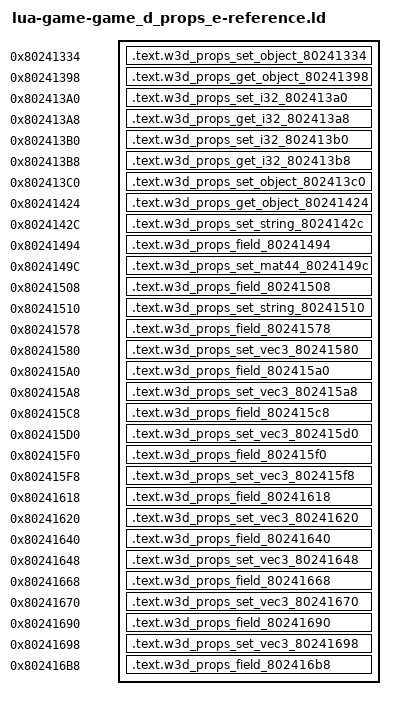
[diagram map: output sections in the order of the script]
/* Generated reference-only placements. All bodies are source-built. */
OUTPUT_FORMAT("elf32-powerpc")
OUTPUT_ARCH(powerpc)
ENTRY(w3d_props_set_object_80241334)
_SDA_BASE_ = 0x804b2540;
_SDA2_BASE_ = 0x804c2540;
w3d_string_release_header = 0x8020bb2c;
SECTIONS {
  .text.w3d_props_set_object_80241334 0x80241334 : { *(.text.w3d_props_set_object_80241334) }
  .text.w3d_props_get_object_80241398 0x80241398 : { *(.text.w3d_props_get_object_80241398) }
  .text.w3d_props_set_i32_802413a0 0x802413a0 : { *(.text.w3d_props_set_i32_802413a0) }
  .text.w3d_props_get_i32_802413a8 0x802413a8 : { *(.text.w3d_props_get_i32_802413a8) }
  .text.w3d_props_set_i32_802413b0 0x802413b0 : { *(.text.w3d_props_set_i32_802413b0) }
  .text.w3d_props_get_i32_802413b8 0x802413b8 : { *(.text.w3d_props_get_i32_802413b8) }
  .text.w3d_props_set_object_802413c0 0x802413c0 : { *(.text.w3d_props_set_object_802413c0) }
  .text.w3d_props_get_object_80241424 0x80241424 : { *(.text.w3d_props_get_object_80241424) }
  .text.w3d_props_set_string_8024142c 0x8024142c : { *(.text.w3d_props_set_string_8024142c) }
  .text.w3d_props_field_80241494 0x80241494 : { *(.text.w3d_props_field_80241494) }
  .text.w3d_props_set_mat44_8024149c 0x8024149c : { *(.text.w3d_props_set_mat44_8024149c) }
  .text.w3d_props_field_80241508 0x80241508 : { *(.text.w3d_props_field_80241508) }
  .text.w3d_props_set_string_80241510 0x80241510 : { *(.text.w3d_props_set_string_80241510) }
  .text.w3d_props_field_80241578 0x80241578 : { *(.text.w3d_props_field_80241578) }
  .text.w3d_props_set_vec3_80241580 0x80241580 : { *(.text.w3d_props_set_vec3_80241580) }
  .text.w3d_props_field_802415a0 0x802415a0 : { *(.text.w3d_props_field_802415a0) }
  .text.w3d_props_set_vec3_802415a8 0x802415a8 : { *(.text.w3d_props_set_vec3_802415a8) }
  .text.w3d_props_field_802415c8 0x802415c8 : { *(.text.w3d_props_field_802415c8) }
  .text.w3d_props_set_vec3_802415d0 0x802415d0 : { *(.text.w3d_props_set_vec3_802415d0) }
  .text.w3d_props_field_802415f0 0x802415f0 : { *(.text.w3d_props_field_802415f0) }
  .text.w3d_props_set_vec3_802415f8 0x802415f8 : { *(.text.w3d_props_set_vec3_802415f8) }
  .text.w3d_props_field_80241618 0x80241618 : { *(.text.w3d_props_field_80241618) }
  .text.w3d_props_set_vec3_80241620 0x80241620 : { *(.text.w3d_props_set_vec3_80241620) }
  .text.w3d_props_field_80241640 0x80241640 : { *(.text.w3d_props_field_80241640) }
  .text.w3d_props_set_vec3_80241648 0x80241648 : { *(.text.w3d_props_set_vec3_80241648) }
  .text.w3d_props_field_80241668 0x80241668 : { *(.text.w3d_props_field_80241668) }
  .text.w3d_props_set_vec3_80241670 0x80241670 : { *(.text.w3d_props_set_vec3_80241670) }
  .text.w3d_props_field_80241690 0x80241690 : { *(.text.w3d_props_field_80241690) }
  .text.w3d_props_set_vec3_80241698 0x80241698 : { *(.text.w3d_props_set_vec3_80241698) }
  .text.w3d_props_field_802416b8 0x802416b8 : { *(.text.w3d_props_field_802416b8) }
  /DISCARD/ : { *(.text*) *(.rodata*) *(.data*) *(.bss*) *(.sdata*) *(.sbss*) *(.comment) }
}
